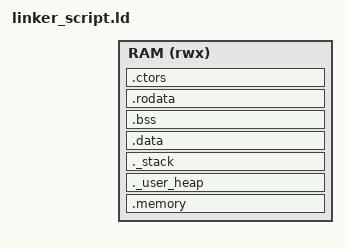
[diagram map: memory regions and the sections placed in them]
/*
This is free and unencumbered software released into the public domain.

Anyone is free to copy, modify, publish, use, compile, sell, or
distribute this software, either in source code form or as a compiled
binary, for any purpose, commercial or non-commercial, and by any
means.
*/
OUTPUT_FORMAT("elf32-littleriscv", "elf32-littleriscv", "elf32-littleriscv")
OUTPUT_ARCH(riscv)
ENTRY(crtStart)

MEMORY {
  RAM      (rwx): ORIGIN = SECTION_START, LENGTH = (MEMSIZE - SECTION_START)
}

_stack_size = STACK_SIZE;
_heap_size = HEAP_SIZE;

SECTIONS {

  .memory : {
    *(.start_jump);
    *(.text);
  } > RAM
  
  ._user_heap (NOLOAD):
  {
    . = ALIGN(8);
    PROVIDE ( end = . );
    PROVIDE ( _end = . );
    PROVIDE ( _heap_start = .);
    . = . + _heap_size;
    . = ALIGN(8);
    PROVIDE ( _heap_end = .);
  } > RAM

  ._stack (NOLOAD):
  {
    . = ALIGN(16);
    PROVIDE (_stack_end = .);
    . = . + _stack_size;
    . = ALIGN(16);
    PROVIDE (_stack_start = .);
  } > RAM

  .data :
  {
    *(.rdata)
    *(.rodata .rodata.*)
    *(.gnu.linkonce.r.*)
    *(.data .data.*)
    *(.gnu.linkonce.d.*)
    . = ALIGN(8);
    PROVIDE( __global_pointer$ = . + 0x800 );
    *(.sdata .sdata.*)
    *(.gnu.linkonce.s.*)
    . = ALIGN(8);
    *(.srodata.cst16)
    *(.srodata.cst8)
    *(.srodata.cst4)
    *(.srodata.cst2)
    *(.srodata .srodata.*)
  } > RAM

  .bss (NOLOAD) : {
		. = ALIGN(4);
		/* This is used by the startup in order to initialize the .bss section */
    _sbss = .;
		__bss_start__ = _sbss;
    __dso_handle = _sbss;
    *(.sbss*)
    *(.gnu.linkonce.sb.*)
    *(.bss .bss.*)
    *(.gnu.linkonce.b.*)
    *(COMMON)
		. = ALIGN(4);
    _ebss = .;
		__bss_end__ = _ebss;
  } > RAM


  .rodata         :
  {
    *(.rdata)
    *(.rodata .rodata.*)
    *(.gnu.linkonce.r.*)
  } > RAM
/*
  .memory : {
    *(.text);
    end = .;
  } > RAM
*/
  .ctors          :
  {
    . = ALIGN(4);
    _ctors_start = .;
    KEEP(*(.init_array*))
    KEEP (*(SORT(.ctors.*)))
    KEEP (*(.ctors))
    . = ALIGN(4);
    _ctors_end = .;
    PROVIDE ( END_OF_SW_IMAGE = . );
  } > RAM
}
